# MMCSD_MMC_48300000h register map
Vendor: Texas Instruments
Registers are 32-bit, access per field, reset values left out (the file's numbers can be read two ways) unless marked. A register's access mark holds for its fields unless they carry their own. Offsets are as the file gives them; [hi:lo] are bit positions.

## MMC (part 2 of 3)
0x220 MMC_DATA rw — Data RegisterThis register is the 32-bit entry point of the buffer for read or write data transfers.The buffer size is 32bits x256(1024 bytes). Bytes within a word are stored and read in little endian format. This buffer can be used as two 512 byte buffers to transfer data efficiently without reducing the throughput.Sequential and contiguous access is necessary to increment the pointer correctly. Random or skipped access is not allowed. In little endian, if the local host accesses this register byte-wise or 16bit-wise, the least significant byte (bits [7:0]) must always be written/read first. The update of the buffer address is done on the most significant byte write for full 32-bit DATA register or on the most significant byte of the last word of block transfer.Example 1: Byte or 16-bit accessMbyteen[3:0]=0001 (1-byte) => Mbyteen[3:0]=0010 (1-byte) => Mbyteen[3:0]=1100 (2-bytes) OKMbyteen[3:0]=0001 (1-byte) => Mbyteen[3:0]=0010 (1-byte) => Mbyteen[3:0]=0100 (1-byte) OKMbyteen[3:0]=0001 (1-byte) => Mbyteen[3:0]=0010 (1-byte) => Mbyteen[3:0]=1000 (1-byte) Bad .
  [31:0] DATA — Data Register [31:0]In functional mode [MMCSD_CON[MODE] set to the default value 0] ,A read access to this register is allowed only when the buffer read enable status is set to 1 [MMCSD_PSTATE[BRE]], otherwise a bad access [MMCSD_STAT[BADA]] is signaled.A write access to this register is allowed only when the buffer write enable status is set to 1[MMCSD_STATE[BWE]], otherwise a bad access [MMCSD_STAT[BADA]] is signaled and the data is not written.
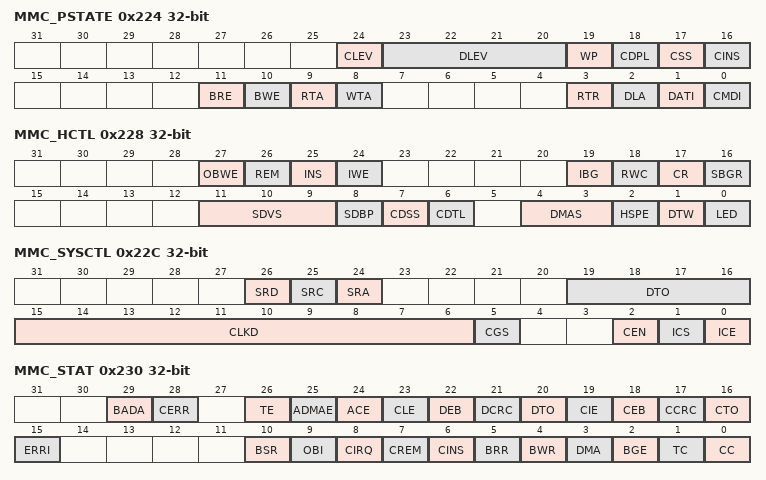
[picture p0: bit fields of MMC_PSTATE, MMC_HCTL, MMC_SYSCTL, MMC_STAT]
0x224 MMC_PSTATE ro — Present State Register The Host can get status of the Host Controller from this 32-bit read only register.
  [24] CLEV — CMD line signal levelThis status is used to check the CMD line level to recover from errors, and for debugging.The value of this register after reset depends on the CMD line level at that time. 0 The CMD line level is 0.1 The CMD line level is 1.
  [23:20] DLEV — DAT[3:0] line signal levelDAT[3] => bit 23DAT[2] => bit 22DAT[1] => bit 21DAT[0] => bit 20This status is used to check DAT line level to recover from errors, and for debugging. This is especially useful in detecting the busy signal level from DAT[0].The value of these registers after reset depends on the DAT lines level at that time.
  [19] WP — Write protect switch pin levelFor SDIO cards only.This bit reflects the write protect input pin [SDWP] level.The value of this register after reset depends on the protect input pin [SDWP] level at that time. 0 If MMCHS_CON[WPP] is set to 0 (default), the card is write protected, otherwise the card is not protected.1 If MMCHS_CON[WPP] is set to 0 (default), the card is not write protected, otherwise the card is protected.
  [18] CDPL — Card detect pin levelThis bit reflects the inverse value of the card detect input pin [SDCD], debouncing is not performed on this bit and bit is valid only when Card State Stable [MMCSD_PSTAE[CSS]] is set to 1.Use of this bit is limited to testing since it must be debounced y software.The value of this register after reset depends on the card detect input pin [SDCD] level at that time. 0 The value of the card detect input pin (SDCD) is 11 The value of the card detect input pin (SDCD) is 0
  [17] CSS — Card State StableThis bit is used for testing. It is set to 1 only when Card Detect Pin Level is stable [MMCSD_PSTATE[CDPL]]. Debouncing is performed on the card detect input pin [SDCD] to detect card stability.This bit is not affected by a software reset. 0 Reset or Debouncing1 No card or card inserted
  [16] CINS — Card insertedThis bit is the debounced value of the card detect input pin [SDCD].An inactive to active transition of the card detect input pin [SDCD] will generate a card insertion interrupt [MMCSD_STAT[CINS]].A active to inactive transition of the card detect input pin [SDCD] will generate a card removal interrupt [MMCSD_STAT[REM]].This bit is not affected by a software reset. 0 If MMCHS_CON[CDP] is set to 1, no card is detected. The card may have been removed from the card slot. If MMCHS_CON[CDP] is set to 0, the card has been inserted.1 If MMCHS_CON[CDP] is set to 1, the card has been inserted from the card slot. If MMCHS_CON[CDP] is set to 0 no card is detected. The card may have been removed from the card slot.
  [11] BRE — Buffer read enableThis bit is used for non-DMA read transfers.It indicates that a complete block specified by MMCSD_BLK[BLEN] has been written in the buffer and is ready to be read.It is set to 0 when the entire block is read from the buffer. It is set to 1 when a block data is ready in the buffer and generates the Buffer read ready status of interrupt [MMCSD_STAT[BRR]]. 0 Read BLEN bytes disable1 Read BLEN bytes enable. Readable data exists in the buffer.
  [10] BWE — Buffer Write enableThis status is used for non-DMA write transfers.It indicates if space is available for write data. 0 There is no room left in the buffer to write BLEN bytes of data.1 There is enough space in the buffer to write BLEN bytes of data.
  [9] RTA — Read transfer activeThis status is used for detecting completion of a read transfer. It is set to 1 after the end bit of read command or by activating a continue request [MMCSD_HCTL[CR]] following a stop at block gap request. This bit is set to 0 when all data have been read by the local host after last block or after a stop at block gap request. 0 No valid data on the DAT lines.1 read data transfer on going.
  [8] WTA — Write transfer activeThis status indicates a write transfer active. It is set to 1 after the end bit of write command or by activating a continue request [MMCSD_HCTL[CR]] following a stop at block gap request. This bit is set to 0 when CRC status has been received after last block or after a stop at block gap request. 0 No valid data on the DAT lines.1 Write data transfer on going.
  [3] RTR — Re-Tuning Request Host Controller may request Host Driver to execute re-tuning sequence by setting this bit when the data window is shifted by temperature drift and a tuned sampling point does not have a good margin to receive correct data. This bit is cleared when a command is issued with setting Execute Tuning in the Host Control 2 register. Changing of this bit from 0 to 1 generates Re-Tuning Event. Refer to Normal Interrupt Status registers for more detail. This bit isn't set to 1 if Sampling Clock Select in the Host Control 2 register is set to 0 [using fixed sampling clock]. Refer to Re-Tuning Modes in the Capabilities register for more detail. 0 Fixed or well tuned sampling clock1 Sampling clock needs re-tuning
  [2] DLA — DAT line activeThis status bit indicates whether one of the DAT line is in use.In the case of read transactions [card to host]:This bit is set to 1 after the end bit of read command or by activating continue request MMCSD_HCTL[CR].This bit is set to 0 when the host controller received the end bit of the last data block or at the beginning of the read wait mode.In the case of write transactions [host to card]:This bit is set to 1 after the end bit of write command or by activating continue request MMCSD_HCTL[CR].This bit is set to 0 on the end of busy event for the last block; host controller must wait 8 clock cycles with line not busy to really consider not 'busy state' or after the busy block as a result of a stop at gap request. 0 DAT Line inactive1 DAT Line active
  [1] DATI — Command inhibit[DAT]This status bit is generated if either DAT line is active [MMCSD_PSTATE[DLA]] or Read transfer is active [MMCSD_PSTATE[RTA]] or when a command with busy is issued. This bit prevents the local host to issue a command.A change of this bit from 1 to 0 generates a transfer complete interrupt [MMCSD_STAT[TC]]. 0 Issuing of command using the DAT lines is allowed1 Issuing of command using DAT lines is not allowed
  [0] CMDI — Command inhibit[CMD]This status bit indicates that the CMD line is in use.This bit is set to 0 when the most significant byte is written into the command register. This bit is not set when Auto CMD12 is transmitted.This bit is set to 0 in either the following cases: - After the end bit of the command response, excepted if there is a command conflict error [MMCSD_STAT[CCRC] or MMCSD_STAT[CEB] set to 1] or a Auto CMD12 is not executed [MMCSD_AC12[ACNE]].- After the end bit of the command without response [MMCSD_CMD[RSP_TYPE] set to '00']In case of a command data error is detected [MMCSD_STAT[CTO] set to 1], this register is not automatically cleared. 0 Issuing of command using CMD line is allowed1 Issuing of command using CMD line is not allowed
0x228 MMC_HCTL — Host Control Register This register defines the host controls to set power, wakeup and transfer parameters. MMCHS_HCTL[31:24] = Wakeup control MMCHS_HCTL[23:16] = Block gap control MMCHS_HCTL[15:8] = Power control MMCHS_HCTL[7:0] = Host control.
  [27] OBWE rw — Wakeup event enable for 'Out-of-Band' Interrupt.This bit enables wakeup events for 'Out-of-Band' assertion. Wakeup is generated if the wakeup feature is enabled [MMCSD_SYSCONFIG[ENAWAKEUP]].The write to this register is ignored when MMCSD_CON[OBIE] is not set. 0 Disable wakeup on 'Out-of-Band' Interrupt1 Enable wakeup on 'Out-of-Band' Interrupt
  [26] REM rw — Wakeup event enable on SD card removalThis bit enables wakeup events for card removal assertion. Wakeup is generated if the wakeup feature is enabled [MMCSD_SYSCONFIG[ENAWAKEUP]]. 0 Disable wakeup on card removal1 Enable wakeup on card removal
  [25] INS rw — Wakeup event enable on SD card insertionThis bit enables wakeup events for card insertion assertion. Wakeup is generated if the wakeup feature is enabled [MMCSD_SYSCONFIG[ENAWAKEUP]]. 0 Disable wakeup on card insertion1 Enable wakeup on card insertion
  [24] IWE rw — Wakeup event enable on SD card interruptThis bit enables wakeup events for card interrupt assertion. Wakeup is generated if the wakeup feature is enabled [MMCSD_SYSCONFIG[ENAWAKEUP]]. 0 Disable wakeup on card interrupt1 Enable wakeup on card interrupt
  [19] IBG rw — Interrupt block at gapThis bit is valid only in 4-bit mode of SDIO card to enable interrupt detection in the interrupt cycle at block gap for a multiple block transfer. For MMC cards and for SD card this bit should be set to 0. 0 Disable interrupt detection at the block gap in 4-bit mode1 Enable interrupt detection at the block gap in 4-bit mode
  [18] RWC rw — Read wait controlThe read wait function is optional only for SDIO cards. If the card supports read wait, this bit must be enabled, then requesting a stop at block gap [MMCSD_HCTL[SBGR]] generates a read wait period after the current end of block. Be careful, if read wait is not supported it may cause a conflict on DAT line. 0 Disable Read Wait Control. Suspend/Resume cannot be supported.1 Enable Read Wait Control
  [17] CR rw — Continue requestThis bit is used to restart a transaction that was stopped by requesting a stop at block gap [MMCSD_HCTL[SBGR]]. Set this bit to 1 restarts the transfer. The bit is automatically set to 0 by the host controller when transfer has restarted i.e DAT line is active [MMCSD_PSTATE[DLA]] or transferring data [MMCSD_PSTATE[WTA]].The Stop at block gap request must be disabled [MMCSD_HCTL[SBGR]=0] before setting this bit. 0 No affect1 transfer restart
  [16] SBGR rw — Stop at block gap requestThis bit is used to stop executing a transaction at the next block gap. The transfer can restart with a continue request [MMHS_HCTL[CR]] or during a suspend/resume sequence.In case of read transfer, the card must support read wait control.In case of write transfer, the host driver shall set this bit after all block data written. Until the transfer completion [MMCSD_STAT[TC] set to 1], the host driver shall leave this bit set to 1.If this bit is set, the local host shall not write to the data register [MMCSD_DATA]. 0 Transfer mode1 Stop at block gap
  [11:9] SDVS rw — SD bus voltage select All cards. The host driver should set to these bits to select the voltage level for the card according to the voltage supported by the system [MMCSD_CAPA[VS18,VS30,VS33]] before starting a transfer. 5 1.8V (Typical)6 3.0V (Typical)7 3.3V (Typical)
  [8] SDBP rw — SD bus powerBefore setting this bit, the host driver shall select the SD bus voltage [MMCSD_HCTL[SDVS]]. If the host controller detects the No card state, this bit is automatically set to 0. If the module is power off, a write in the command register [MMCSD_CMD] will not start the transfer. A write to this bit has no effect if the selected SD bus voltage MMCSD_HCTL[SDVS] is not supported according to capability register [MMCSD_CAPA[VS*]]. 0 Power off1 Power on
  [7] CDSS rw — Card Detect Signal SelectionThis bit selects source for the card detection.When the source for the card detection is switched, the interrupt should be disabled during the switching period by clearing the Interrupt Status/Signal Enable register in order to mask unexpected interrupt being caused by the glitch. The Interrupt Status/Signal Enable should be disabled during over the period of debouncing. 0 SDCD# is selected (for normal use)1 The Card Detect Test Level is selected (for test purpose)
  [6] CDTL rw — Card Detect Test Level: This bit is enabled while the Card Detect Signal Selection is set to 1 and it indicates card inserted or not. 0 No Card1 Card Inserted
  [4:3] DMAS rw — DMA Select Mode:One of supported DMA modes can be selected. The host driver shall check support of DMA modes by referring the Capabilities register. Use of selected DMA is determined by DMA Enable of the Transfer Mode register. This register is only meaningful when MADMA_EN is set to 1. When MADMA_EN is set to 0 the bit field is read only and returned value is 0. 0 Reserved1 Reserved2 32-bit Address ADMA2 is selected3 Reserved
  [2] HSPE rw — High Speed Enable:Before setting this bit, the Host Driver shall check the High Speed Support in the Capabilities register. If this bit is set to 0 [default], the Host Controller outputs CMD line and DAT lines at the falling edge of the SD Clock. If this bit is set to 1, the Host Controller outputs CMD line and DAT lines at the rising edge of the SD Clock.This bit shall not be set when dual data rate mode is activated in MMCSD_CON[DDR]. 0 Normal speed mode1 High speed mode
  [1] DTW rw — Data transfer widthFor MMC card, this bit must be set following a valid SWITCH command [CMD6] with the correct value and extend CSD index written in the argument. Prior to this command, the MMC card configuration register [CSD and EXT_CSD] must be verified for compliance with MMC standard specification 4.x [see section 3.6].This register has no effect when the MMC 8-bit mode is selected [register MMCSD_CON[DW8] set to1 ],For SD/SDIO cards, this bit must be set following a valid SET_BUS_WIDTH command [ACMD6] with the value written in bit 1 of the argument. Prior to this command, the SD card configuration register [SCR] must be verified for the supported bus width by the SD card. 0 1-bit Data width (DAT[0] used)1 4-bit Data width (DAT[3:0] used)
  [0] LED ro — Reserved bit.LED control feature is not supported This bit is initialized to zero, and writes to it are ignored.
0x22C MMC_SYSCTL — SD System Control Register This register defines the system controls to set software resets, clock frequency management and data timeout. MMCHS_SYSCTL[31:24] = Software resets MMCHS_SYSCTL[23:16] = Timeout control MMCHS_SYSCTL[15:0] = Clock control.
  [26] SRD rw — Software reset for DAT lineThis bit is set to 1 for reset and released to 0 when completed.DAT finite state machine in both clock domain are also reset.Here below are the registers cleared by MMCSD_SYSCTL[SRD]:- MMCSD_DATA- MMCSD_PSTATE: BRE, BWE, RTA, WTA, DLA and DATI- MMCSD_HCTL: SBGR and CR- MMCSD_STAT: BRR, BWR, BGE and TCOCP and MMC buffer data management is reinitialized. 0 Reset completed1 Software reset for DAT line
  [25] SRC rw — Software reset for CMD lineThis bit is set to 1 for reset and released to 0 when completed.CMD finite state machine in both clock domain are also reset.Here below the registers cleared by MMCSD_SYSCTL[SRC]:- MMCSD_PSTATE: CMDI- MMCSD_STAT: CCOCP and MMC command status management is reinitialized. 0 Reset completed1 Software reset for CMD line
  [24] SRA rw — Software reset for allThis bit is set to 1 for reset , and released to 0 when completed.This reset affects the entire host controller except for the card detection circuit and capabilities registers. 0 Reset completed1 Software reset for all the design
  [19:16] DTO rw — Data timeout counter value and busy timeout.This value determines the interval by which DAT lines timeouts are detected.The host driver needs to set this bitfield based on - the maximum read access time [NAC] [Refer to the SD Specification Part1 Physical Layer], - the data read access time values [TAAC and NSAC] in the card specific data register [CSD] of the card, - the timeout clock base frequency [MMCSD_CAPA[TCF]]. If the card does not respond within the specified number of cycles, a data timeout error occurs [MMCSD_STA[DTO]].The MMCSD_SYSCTL[DTO] register is also used to check busy duration, to generate busy timeout for commands with busy response or for busy programming during a write command. Timeout on CRC status is generated if no CRC token is present after a block write. 0 TCF x 2^131 TCF x 2^1414 TCF x 2^2715 Reserved
  [15:6] CLKD rw — Clock frequency select These bits define the ratio between a reference clock frequency [system dependant] and the output clock frequency on the CLK pin of either the memory card [MMC, SD or SDIO]. 0 Clock Ref bypass1 Clock Ref bypass2 Clock Ref / 23 Clock Ref / 31023 Clock Ref / 1023
  [5] CGS ro — Clock Generator Select - For SD cards Host Controller Version 3.00 supports this bit. This bit is used to select the clock generator mode in SDCLK Frequency Select. If the Programmable Clock Mode is supported [non-zero value is set to Clock Multiplier in the Capabilities register], this bit attribute is RW, and if not supported, this bit attribute is RO and zero is read. This bit depends on the setting of Preset Value Enable in the Host Control 2 register. If the Preset Value Enable = 0, this bit is set by Host Driver. If the Preset Value Enable = 1, this bit is automatically set to a value specified in one of Preset Value registers.
  [2] CEN rw — Clock enableThis bit controls if the clock is provided to the card or not. 0 The clock is not provided to the card . Clock frequency can be changed .1 The clock is provided to the card and can be automatically gated when MMCHS_SYSCONFIG[AUTOIDLE] is set to 1 (default value) . The host driver shall wait to set this bit to 1 until the Internal clock is stable (MMCHS_SYSCTL[ICS]).
  [1] ICS ro — Internal clock stable [status]This bit indicates either the internal clock is stable or not. 0 The internal clock is not stable.1 The internal clock is stable after enabling the clock (MMCHS_SYSCTL[ICE]) or after changing the clock ratio (MMCHS_SYSCTL[CLKD]).
  [0] ICE rw — Internal clock enableThis register controls the internal clock activity.In very low power state, the internal clock is stopped.Note: The activity of the debounce clock [used for wakeup events] and the OCP clock [used for reads and writes to the module register map] are not affected by this register. 0 The internal clock is stopped (very low power state).1 The internal clock oscillates and can be automatically gated when MMCHS_SYSCONFIG[AUTOIDLE] is set to 1 (default value) .
0x230 MMC_STAT — Interrupt Status Register The interrupt status regroups all the status of the module internal events that can generate an interrupt. MMCHS_STAT[31:16] = Error Interrupt Status MMCHS_STAT[15:0] = Normal Interrupt Status.
  [29] BADA rw — Bad access to data spaceThis bit is set automatically to indicate a bad access to buffer when not allowed:-This bit is set during a read access to the data register [MMCSD_DATA] while buffer reads are not allowed [MMCSD_PSTATE[BRE] =0]-This bit is set during a write access to the data register [MMCSD_DATA] while buffer writes are not allowed [MMCSD_STATE[BWE] =0] 0 No Interrupt.0 Status bit unchanged1 Bad Access1 Status is cleared
  [28] CERR rw — Card errorThis bit is set automatically when there is at least one error in a response of type R1, R1b, R6, R5 or R5b. Only bits referenced as type E[error] in status field in the response can set a card status error. An error bit in the response is flagged only if corresponding bit in card status response error MMCSD_CSRE in set.There is no card error detection for autoCMD12 command. The host driver shall read MMCSD_RSP76 register to detect error bits in the command response. 0 No Error0 Status bit unchanged1 Card error1 Status is cleared
  [26] TE rw — Tuning Error This bit is set when an unrecoverable error is detected in a tuning circuit except during tuning procedure [Occurrence of an error during tuning procedure is indicated by Sampling Select]. By detecting Tuning Error, Host Driver needs to abort a command executing and perform tuning. To reset tuning circuit, Sampling Clock shall be set to 0 before executing tuning procedure. The Tuning Error is higher priority than the other error interrupts generated during data transfer. By detecting Tuning Error, the Host Driver should discard data transferred by a current read/write command and retry data transfer after the Host Controller retrieved from tuning circuit error. The bit is set if the lock is lost [but not during the tuning process] or if the lock counter expires without the lock being asserted. If the latter happens, the SW can decide to ignore the interrupt and wait some more for the lock to be set. 0 No Error1 Error
  [25] ADMAE rw — ADMA Error:This bit is set when the Host Controller detects errors during ADMA based data transfer. The state of the ADMA at an error occurrence is saved in the ADMA Error Status Register.In addition, the Host Controller generates this interrupt when it detects invalid descriptor data [Valid=0] at the ST_FDS state. ADMA Error State in the ADMA Error Status indicates that an error occurs in ST_FDS state. The Host Driver may find that Valid bit is not set at the error descriptor. 0 No Interrupt.0 Status bit unchanged1 ADMA error1 Status is cleared
  [24] ACE rw — Auto CMD error Auto CMD12 and Auto CMD23 use this error status. This bit is set when detecting that one of the bits D00-D04 in Auto CMD Error Status register has changed from 0 to 1. In case of Auto CMD12, this bit is set to 1, not only when the errors in Auto CMD12 occur but also when Auto CMD12 is not executed due to the previous command error. 0 No Error.0 Status bit unchanged1 Auto CMD error1 Status is cleared
  [23] CLE ro — Reserved.Current limit error is not supported.These bits are initialized to zero, and writes to them are ignored.
  [22] DEB rw — Data End Bit errorThis bit is set automatically when detecting a 0 at the end bit position of read data on DAT line or at the end position of the CRC status in write mode. 0 No Error0 Status bit unchanged1 Data end bit error1 Status is cleared
  [21] DCRC rw — Data CRC ErrorThis bit is set automatically when there is a CRC16 error in the data phase response following a block read command or if there is a 3-bit CRC status different of a position '010' token during a block write command. 0 No Error.0 Status bit unchanged1 Data CRC error1 Status is cleared
  [20] DTO rw — Data timeout errorThis bit is set automatically according to the following conditions: - busy timeout for R1b, R5b response type - busy timeout after write CRC status- write CRC status timeout- read data timeout 0 No error.0 Status bit unchanged1 Time out1 Status is cleared
  [19] CIE rw — Command index errorThis bit is set automatically when response index differs from corresponding command index previously emitted. It depends on the enable in MMCSD_CMD[CICE] register. 0 No error.0 Status bit unchanged1 Command index error1 Status is cleared
  [18] CEB rw — Command end bit errorThis bit is set automatically when detecting a 0 at the end bit position of a command response. 0 No error.0 Status bit unchanged1 Command end bit error1 Status is cleared
  [17] CCRC rw — Command CRC ErrorThis bit is set automatically when there is a CRC7 error in the command response depending on the enable in MMCSD_CMD[CCCE] register. 0 No Error.0 Status bit unchanged1 Command CRC error1 Status is cleared
  [16] CTO rw — Command Timeout ErrorThis bit is set automatically when no response is received within 64 clock cycles from the end bit of the command.For commands that reply within 5 clock cycles - the timeout is still detected at 64 clock cycles. 0 No error0 Status bit unchanged1 Time Out1 Status is cleared
  [15] ERRI ro — Error InterruptIf any of the bits in the Error Interrupt Status register [MMCSD_STAT[24:15]] are set, then this bit is set to 1. Therefore the host driver can efficiently test for an error by checking this bit first.Writes to this bit are ignored. 0 No Interrupt.1 Error interrupt event(s) occurred
  [10] BSR rw — Boot status received interruptThis bit is set automatically when MMCSD_CON[BOOT] is set 0x1 or 0x2 and a boot status is received on DAT[0] line. This interrupt is only useful for MMC card. 0 No Interrupt.0 Status bit unchanged1 Boot status received interrupt.1 Status is cleared
  [9] OBI rw — Out-Of-Band interruptThis bit is set automatically when MMCSD_CON[OBIE] is set and an Out-of-Band interrupt occurs on OBI pin. The interrupt detection depends on polarity controlled by MMCSD_CON[OBIP].This interrupt is only useful for MMC card.The Out-of-Band interrupt signal is a system specific feature for future use, this signal is not required for existing specification implementation. 0 No Out-Of-Band interrupt.0 Status bit unchanged1 Interrupt Out-Of-Band occurs1 Status is cleared
  [8] CIRQ ro — Card interrupt This bit is only used for SD and SDIO and CE-ATA cards. In 1-bit mode, interrupt source is asynchronous [can be a source of asynchronous wakeup]. In 4-bit mode, interrupt source is sampled during the interrupt cycle. In CE-ATA mode, interrupt source is detected when the card drives CMD line to zero during one cycle after data transmission end.All modes above are fully exclusive. The controller interrupt must be clear by setting MMCSD_IE[CIRQ] to 0, then the host driver must start the interrupt service with card [clearing card interrupt status] to remove card interrupt source. Otherwise the Controller interrupt will be reasserted as soon as MMCSD_IE[CIRQ] is set to 1. Writes to this bit are ignored. 0 No card interrupt1 Generate card interrupt
  [7] CREM rw — Card removalThis bit is set automatically when MMCSD_PSTATE[CINS] changes from 1 to 0.A clear of this bit doesn't effect Card inserted present state [MMCSD_PSTATE[CINS]]. 0 Card state stable or Debouncing0 Status bit unchanged1 Card removed1 Status is cleared
  [6] CINS rw — Card insertionThis bit is set automatically when MMCSD_PSTATE[CINS] changes from 0 to 1.A clear of this bit doesn't effect Card inserted present state [MMCSD_PSTATE[CINS]]. 0 Card state stable or debouncing0 Status bit unchanged1 Card inserted1 Status is cleared
  [5] BRR rw — Buffer read readyThis bit is set automatically during a read operation to the card [see class 2 - block oriented read commands] when one block specified by MMCSD_BLK[BLEN] is completely written in the buffer. It indicates that the memory card has filled out the buffer and that the local host needs to empty the buffer by Reading it. Note: If the DMA receive-mode is enabled, this bit is never set; instead a DMA receive request to the main DMA controller of the system is generated. 0 Not Ready to read buffer0 Status bit unchanged1 Ready to read buffer1 Status is cleared
  [4] BWR rw — Buffer write readyThis bit is set automatically during a write operation to the card [see class 4 - block oriented write command] when the host can write a complete block as specified by MMCSD_BLK[BLEN]. It indicates that the memory card has emptied one block from the buffer and that the local host is able to write one block of data into the buffer. Note: If the DMA transmit mode is enabled, this bit is never set; instead, a DMA transmit request to the main DMA controller of the system is generated. 0 Not Ready to write buffer0 Status bit unchanged1 Ready to write buffer1 Status is cleared
  [3] DMA rw — DMA interrupt :This status is set when an interrupt is required in the ADMA instruction and after the data transfer completion. 0 Dma interrupt detected0 Status bit unchanged1 No dma interrupt1 Status is cleared
  [2] BGE rw — Block gap eventWhen a stop at block gap is requested [MMCSD_HCTL[SBGR]], this bit is automatically set when transaction is stopped at the block gap during a read or write operation.This event does not occur when the stop at block gap is requested on the last block.In read mode, a 1-to-0 transition of the DAT Line active status [MMCSD_PSTATE[DLA]] between data blocks generates a Block gap event interrupt. 0 No block gap event0 Status bit unchanged1 Transaction stopped at block gap1 Status is cleared
  [1] TC rw — Transfer completedThis bit is always set when a read/write transfer is completed or between two blocks when the transfer is stopped due to a stop at block gap request [MMCSD_HCTL[SBGR]].In Read mode:This bit is automatically set on completion of a read transfer [MMCSD_PSTATE[RTA]].In write mode:This bit is set automatically on completion of the DAT line use [MMCSD_PSTATE[DLA]]. 0 No transfer complete0 Status bit unchanged1 Data transfer complete1 Status is cleared
  [0] CC rw — Command completeThis bit is set when a 1-to-0 transition occurs in the register command inhibit [MMCSD_PSTATE[CMDI]]If the command is a type for which no response is expected, then the command complete interrupt is generated at the end of the command.A command timeout error [MMCSD_STAT[CTO]] has higher priority than command complete [MMCSD_STAT[CC]].If a response is expected but none is received, then a command timeout error is detected and signaled instead of the command complete interrupt. 0 No Command complete0 Status bit unchanged1 Command complete1 Status is cleared
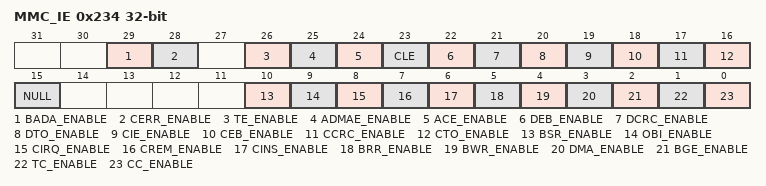
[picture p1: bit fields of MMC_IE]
0x234 MMC_IE — Interrupt Status Enable Register This register allows to enable/disable the module to set status bits, on an event-by-event basis. MMCHS_IE[31:16] = Error Interrupt Status Enable MMCHS_IE[15:0] = Normal Interrupt Status Enable.
  [29] BADA_ENABLE rw — Bad access to data space Status Enable 0 Masked1 Enabled
  [28] CERR_ENABLE rw — Card Error Status Enable 0 Masked1 Enabled
  [26] TE_ENABLE rw — Tuning Error Status Enable 0 Masked1 Enabled
  [25] ADMAE_ENABLE rw — ADMA Error Status Enable 0 Masked1 Enabled
  [24] ACE_ENABLE rw — Auto CMD Error Status Enable 0 Masked1 Enabled
  [23] CLE ro — Reserved bit. Current limit error is not supported. These bits are initialized to zero, and writes to them are ignored.
  [22] DEB_ENABLE rw — Data End Bit Error Status Enable 0 Masked1 Enabled
  [21] DCRC_ENABLE rw — Data CRC Error Status Enable 0 Masked1 Enabled
  [20] DTO_ENABLE rw — Data Timeout Error Status Enable 0 The data timeout detection is deactivated. The host controller provides the clock to the card until the card sends the data or the transfer is aborted.1 The data timeout detection is enabled.
  [19] CIE_ENABLE rw — Command Index Error Status Enable 0 Masked1 Enabled
  [18] CEB_ENABLE rw — Command End Bit Error Status Enable 0 Masked1 Enabled
  [17] CCRC_ENABLE rw — Command CRC Error Status Enable 0 Masked1 Enabled
  [16] CTO_ENABLE rw — Command Timeout Error Status Enable 0 Masked1 Enabled
  [15] NULL ro — Fixed to 0 The host driver shall control error interrupts using the Error Interrupt Signal Enable register. Writes to this bit are ignored
  [10] BSR_ENABLE rw — Boot Status Enable A write to this register when MMCSD_CON[BOOT_ACK] is set to 0x0 is ignored. 0 Masked1 Enabled
  [9] OBI_ENABLE rw — Out-of-Band Status Enable A write to this register when MMCSD_CON[OBIE] is set to '0' is ignored. 0 Masked1 Enabled
  [8] CIRQ_ENABLE rw — Card Status Enable A clear of this bit also clears the corresponding status bit. During 1-bit mode, if the interrupt routine doesn't remove the source of a card interrupt in the SDIO card, the status bit is reasserted when this bit is set to 1. 0 Masked1 Enabled
  [7] CREM_ENABLE rw — Card Removal Status Enable 0 Masked1 Enabled
  [6] CINS_ENABLE rw — Card Insertion Status Enable 0 Masked1 Enabled
  [5] BRR_ENABLE rw — Buffer Read Ready Status Enable 0 Masked1 Enabled
  [4] BWR_ENABLE rw — Buffer Write Ready Status Enable 0 Masked1 Enabled
  [3] DMA_ENABLE rw — DMA Status Enable 0 Masked1 Enabled
  [2] BGE_ENABLE rw — Block Gap Event Status Enable 0 Masked1 Enabled
  [1] TC_ENABLE rw — Transfer Complete Status Enable 0 Masked1 Enabled
  [0] CC_ENABLE rw — Command Complete Status Enable 0 Masked1 Enabled
